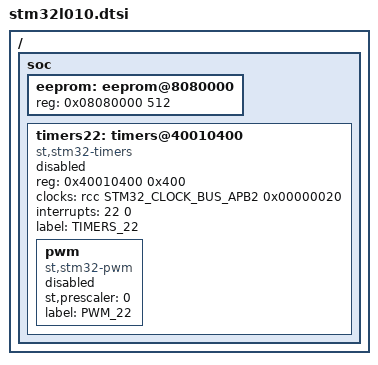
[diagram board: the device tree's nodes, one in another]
/*
 * Copyright (c) 2019-2020 Grinn
 *
 * SPDX-License-Identifier: Apache-2.0
 */

#include <st/l0/stm32l0.dtsi>

/ {
	soc {
		eeprom: eeprom@8080000{
			reg = <0x08080000 512>;
		};

		/* This might be possible to put into stm32l0.dtsi (included above) */
		timers22: timers@40010400 {
			compatible = "st,stm32-timers";
			reg = <0x40010400 0x400>;
			clocks = <&rcc STM32_CLOCK_BUS_APB2 0x00000020>;
			interrupts = <22 0>;
			interrupt-names = "global";
			status = "disabled";
			label = "TIMERS_22";

			pwm {
				compatible = "st,stm32-pwm";
				status = "disabled";
				st,prescaler = <0>;
				label = "PWM_22";
				#pwm-cells = <3>;
			};
		};
	};
};
